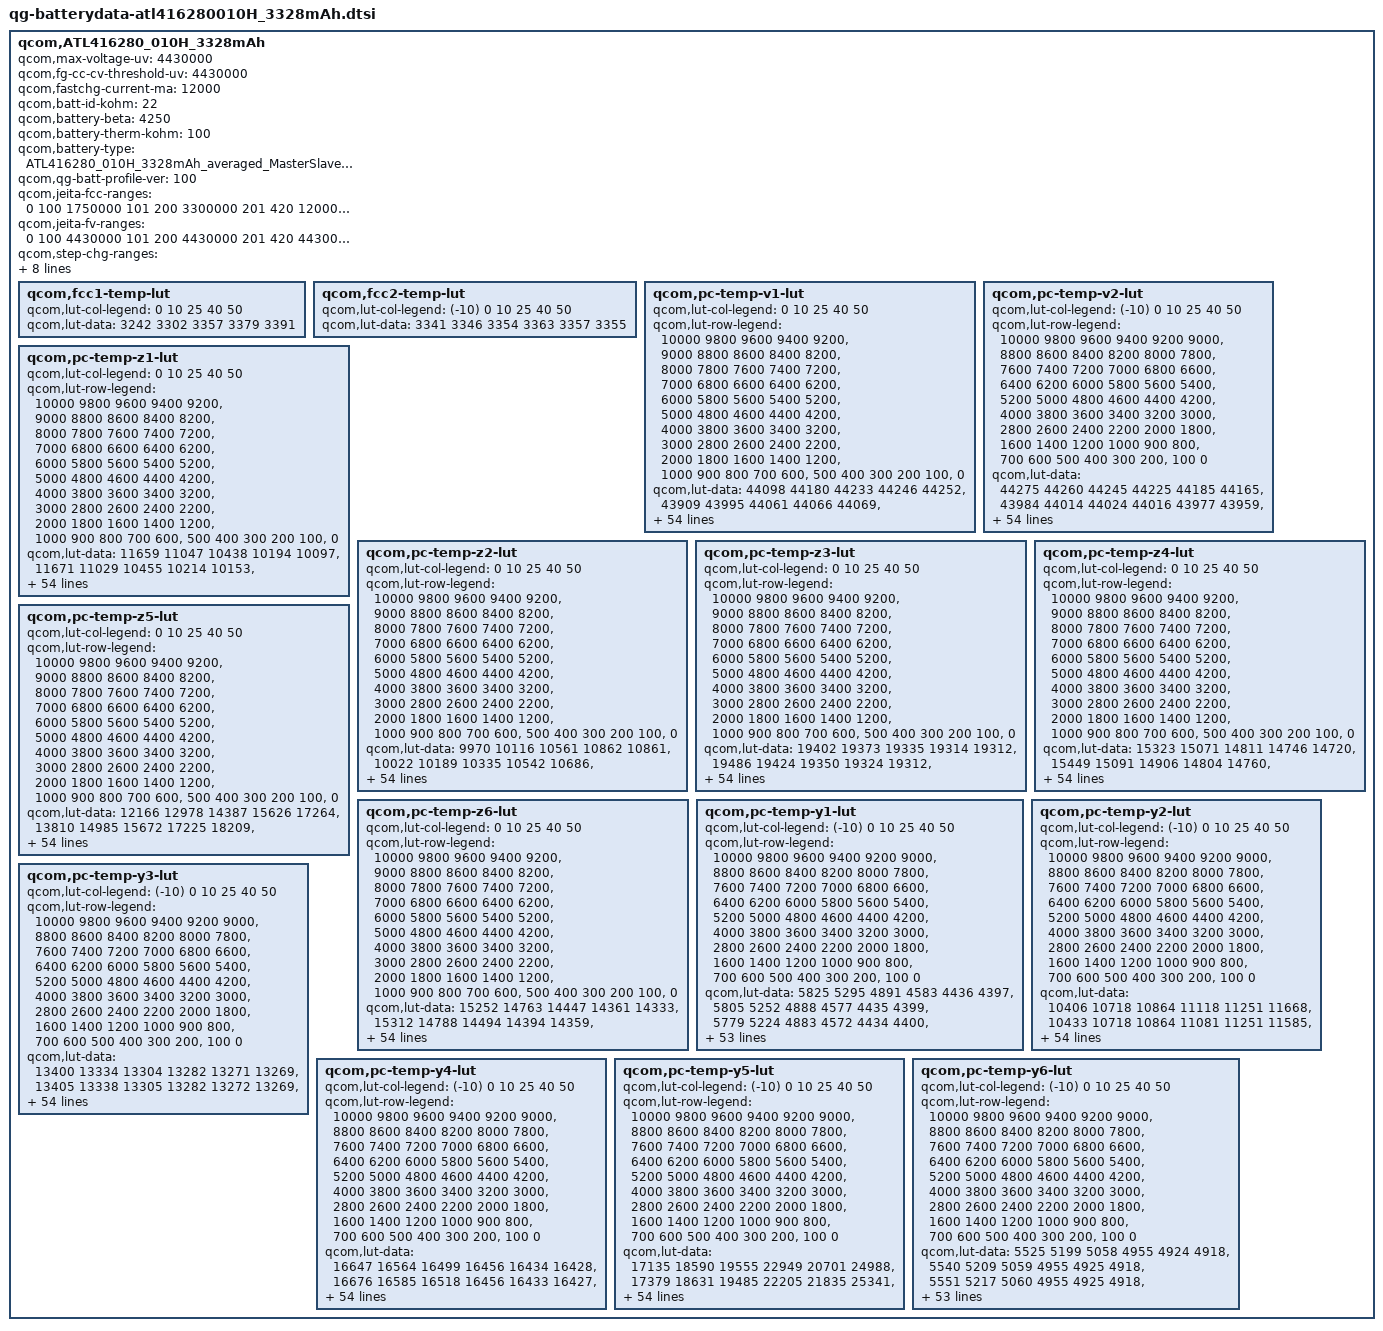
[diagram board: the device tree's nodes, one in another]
qcom,ATL416280_010H_3328mAh {
	/* ATL416280_010H_3328mAh_averaged_MasterSlave_Aug1th2020 */
	qcom,max-voltage-uv = <4430000>;
	qcom,fg-cc-cv-threshold-uv = <4430000>;
	qcom,fastchg-current-ma = <12000>;
	qcom,batt-id-kohm = <22>;
	qcom,battery-beta = <4250>;
	qcom,battery-therm-kohm = <100>;
	qcom,battery-type = "ATL416280_010H_3328mAh_averaged_MasterSlave_Aug1th2020";
	qcom,qg-batt-profile-ver = <100>;

	qcom,jeita-fcc-ranges = <0  100  1750000
				101 200  3300000
				201 420  12000000
				421 434  8000000
				435 450  7000000
				451 550  1750000>;
	qcom,jeita-fv-ranges = <0   100  4430000
				101 200  4430000
				201 420  4430000
				421 434  4430000
				435 450  4430000
				451 550  4100000>;
	qcom,step-chg-ranges = <3500000  4000000  12000000
				4000001  4200000  8000000
				4200001  4400000  6000000>;

	qcom,ocv-based-step-chg;
	/* Rise-Hys = 1 DeciDegC, Fall-Hys=10 deciDegC */
	qcom,step-jeita-hysteresis = <1 10>;
	/* COOL = 10 degc, WARM = 45 degC */
	qcom,jeita-soft-thresholds = <0x4ccc 0x20b8>;
	/* COLD = 0 degC, HOT = 55 degC*/
	qcom,jeita-hard-thresholds = <0x58cd 0x181d>;
	/* COOL hys = 13 degC, WARM hys = 42 degC */
	qcom,jeita-soft-hys-thresholds = <0x48d4 0x23c0>;
	qcom,jeita-soft-fcc-ua = <1750000 1750000>;
	qcom,jeita-soft-fv-uv = <4430000 4100000>;

	qcom,fcc1-temp-lut {
		qcom,lut-col-legend = <0 10 25 40 50>;
		qcom,lut-data = <3242 3302 3357 3379 3391>;
	};

	qcom,fcc2-temp-lut {
		qcom,lut-col-legend = <(-10) 0 10 25 40 50>;
		qcom,lut-data = <3341 3346 3354 3363 3357 3355>;
	};

	qcom,pc-temp-v1-lut {
		qcom,lut-col-legend = <0 10 25 40 50>;
		qcom,lut-row-legend = <10000 9800 9600 9400 9200>,
			<9000 8800 8600 8400 8200>,
			<8000 7800 7600 7400 7200>,
			<7000 6800 6600 6400 6200>,
			<6000 5800 5600 5400 5200>,
			<5000 4800 4600 4400 4200>,
			<4000 3800 3600 3400 3200>,
			<3000 2800 2600 2400 2200>,
			<2000 1800 1600 1400 1200>,
			<1000 900 800 700 600>,
			<500 400 300 200 100>,
			<0>;
		qcom,lut-data = <44098 44180 44233 44246 44252>,
			<43909 43995 44061 44066 44069>,
			<43705 43801 43872 43881 43883>,
			<43488 43600 43675 43687 43692>,
			<43266 43388 43468 43485 43492>,
			<43036 43167 43250 43272 43280>,
			<42803 42933 43024 43049 43059>,
			<42570 42694 42788 42815 42828>,
			<42337 42459 42550 42577 42592>,
			<42108 42224 42310 42340 42357>,
			<41884 41993 42071 42103 42121>,
			<41664 41767 41836 41868 41887>,
			<41448 41545 41606 41636 41655>,
			<41237 41324 41380 41407 41425>,
			<41030 41106 41160 41185 41202>,
			<40832 40899 40947 40969 40984>,
			<40639 40702 40742 40761 40775>,
			<40451 40513 40544 40561 40575>,
			<40276 40334 40354 40367 40382>,
			<40089 40161 40180 40188 40200>,
			<39853 39958 39999 40011 40022>,
			<39582 39678 39766 39793 39811>,
			<39373 39405 39491 39524 39545>,
			<39227 39230 39274 39293 39307>,
			<39106 39100 39118 39127 39139>,
			<38995 38979 38986 38988 38998>,
			<38895 38860 38860 38860 38868>,
			<38802 38751 38746 38743 38748>,
			<38713 38654 38641 38636 38638>,
			<38631 38565 38544 38537 38534>,
			<38558 38484 38455 38445 38438>,
			<38490 38409 38373 38358 38349>,
			<38430 38341 38297 38277 38267>,
			<38374 38282 38231 38203 38190>,
			<38323 38230 38175 38142 38123>,
			<38276 38182 38122 38082 38055>,
			<38238 38140 38068 38014 37975>,
			<38193 38097 38013 37939 37885>,
			<38116 38027 37940 37854 37788>,
			<38003 37919 37837 37754 37682>,
			<37879 37797 37720 37642 37567>,
			<37742 37666 37593 37514 37436>,
			<37590 37521 37452 37370 37291>,
			<37414 37347 37288 37207 37133>,
			<37268 37201 37151 37083 37015>,
			<37186 37123 37070 37016 36960>,
			<37165 37094 37046 37000 36942>,
			<37137 37072 37031 36984 36926>,
			<37105 37045 37004 36958 36896>,
			<37020 36948 36883 36809 36725>,
			<36678 36608 36539 36461 36372>,
			<36216 36138 36070 35995 35905>,
			<35609 35533 35468 35397 35306>,
			<34786 34707 34651 34586 34492>,
			<33476 33410 33391 33343 33244>,
			<30000 30000 30000 30000 30000>;
	};

	qcom,pc-temp-v2-lut {
		qcom,lut-col-legend = <(-10) 0 10 25 40 50>;
		qcom,lut-row-legend = <10000 9800 9600 9400 9200 9000>,
			<8800 8600 8400 8200 8000 7800>,
			<7600 7400 7200 7000 6800 6600>,
			<6400 6200 6000 5800 5600 5400>,
			<5200 5000 4800 4600 4400 4200>,
			<4000 3800 3600 3400 3200 3000>,
			<2800 2600 2400 2200 2000 1800>,
			<1600 1400 1200 1000 900 800>,
			<700 600 500 400 300 200>,
			<100 0>;
		qcom,lut-data = <44275 44260 44245 44225 44185 44165>,
			<43984 44014 44024 44016 43977 43959>,
			<43712 43777 43806 43807 43768 43752>,
			<43460 43552 43593 43599 43560 43545>,
			<43231 43339 43387 43392 43353 43338>,
			<43003 43122 43174 43178 43139 43124>,
			<42768 42890 42942 42949 42911 42898>,
			<42529 42651 42702 42713 42676 42664>,
			<42287 42411 42464 42476 42441 42430>,
			<42038 42168 42223 42235 42203 42193>,
			<41795 41929 41986 41997 41967 41958>,
			<41553 41694 41750 41761 41733 41724>,
			<41322 41466 41518 41529 41503 41495>,
			<41123 41245 41291 41300 41276 41269>,
			<40954 41029 41068 41076 41055 41049>,
			<40762 40821 40853 40859 40841 40835>,
			<40509 40629 40648 40651 40635 40630>,
			<40228 40433 40445 40447 40435 40430>,
			<39961 40192 40228 40253 40245 40241>,
			<39697 39904 40000 40066 40064 40061>,
			<39454 39638 39767 39855 39860 39858>,
			<39239 39411 39515 39587 39596 39595>,
			<39041 39206 39275 39324 39333 39333>,
			<38861 39024 39085 39127 39137 39140>,
			<38695 38861 38925 38961 38976 38983>,
			<38542 38712 38780 38815 38833 38843>,
			<38393 38578 38648 38686 38706 38717>,
			<38263 38454 38529 38570 38592 38603>,
			<38174 38335 38418 38462 38485 38494>,
			<38109 38221 38314 38361 38386 38393>,
			<38052 38123 38219 38268 38294 38300>,
			<38001 38035 38132 38182 38211 38217>,
			<37953 37961 38050 38102 38132 38138>,
			<37902 37908 37970 38026 38055 38057>,
			<37850 37867 37893 37952 37980 37975>,
			<37793 37825 37826 37872 37889 37876>,
			<37728 37783 37772 37784 37772 37742>,
			<37655 37737 37716 37692 37651 37607>,
			<37572 37673 37645 37596 37550 37502>,
			<37477 37592 37562 37495 37454 37409>,
			<37369 37492 37463 37390 37350 37306>,
			<37239 37362 37338 37280 37238 37193>,
			<37109 37208 37195 37153 37108 37062>,
			<36989 37019 37034 37010 36963 36912>,
			<36895 36892 36919 36904 36873 36829>,
			<36811 36821 36864 36877 36848 36802>,
			<36770 36790 36842 36858 36832 36787>,
			<36718 36750 36809 36829 36813 36768>,
			<36641 36688 36750 36777 36763 36707>,
			<36482 36528 36596 36595 36554 36469>,
			<36148 36188 36240 36193 36155 36060>,
			<35657 35691 35728 35665 35634 35532>,
			<35006 35042 35063 34994 34970 34860>,
			<34121 34151 34173 34099 34095 33987>,
			<32801 32865 32898 32797 32800 32602>,
			<29522 29510 29509 29510 29511 29509>;
	};

	qcom,pc-temp-z1-lut {
		qcom,lut-col-legend = <0 10 25 40 50>;
		qcom,lut-row-legend = <10000 9800 9600 9400 9200>,
			<9000 8800 8600 8400 8200>,
			<8000 7800 7600 7400 7200>,
			<7000 6800 6600 6400 6200>,
			<6000 5800 5600 5400 5200>,
			<5000 4800 4600 4400 4200>,
			<4000 3800 3600 3400 3200>,
			<3000 2800 2600 2400 2200>,
			<2000 1800 1600 1400 1200>,
			<1000 900 800 700 600>,
			<500 400 300 200 100>,
			<0>;
		qcom,lut-data = <11659 11047 10438 10194 10097>,
			<11671 11029 10455 10214 10153>,
			<11655 11012 10446 10216 10156>,
			<11617 10994 10437 10216 10157>,
			<11593 10970 10431 10216 10157>,
			<11584 10953 10426 10213 10156>,
			<11576 10938 10421 10210 10154>,
			<11557 10928 10416 10208 10153>,
			<11515 10925 10412 10206 10153>,
			<11490 10923 10409 10204 10153>,
			<11497 10921 10406 10201 10153>,
			<11509 10918 10404 10200 10153>,
			<11510 10914 10402 10201 10152>,
			<11503 10910 10401 10201 10151>,
			<11498 10907 10402 10201 10151>,
			<11499 10905 10402 10200 10152>,
			<11501 10903 10403 10200 10153>,
			<11502 10902 10402 10202 10153>,
			<11502 10901 10403 10203 10154>,
			<11502 10899 10404 10204 10155>,
			<11503 10901 10406 10205 10156>,
			<11509 10906 10409 10207 10158>,
			<11512 10913 10414 10209 10159>,
			<11514 10923 10418 10211 10160>,
			<11517 10937 10421 10213 10161>,
			<11519 10943 10424 10216 10162>,
			<11527 10939 10428 10218 10164>,
			<11537 10934 10433 10220 10166>,
			<11555 10934 10437 10222 10167>,
			<11574 10941 10440 10225 10169>,
			<11575 10944 10444 10227 10169>,
			<11562 10940 10448 10229 10171>,
			<11550 10937 10453 10232 10173>,
			<11543 10941 10458 10235 10176>,
			<11537 10956 10463 10238 10178>,
			<11538 10970 10468 10241 10180>,
			<11555 10977 10474 10244 10182>,
			<11572 10984 10480 10247 10185>,
			<11581 10994 10485 10250 10187>,
			<11596 11009 10489 10252 10190>,
			<11607 11021 10493 10254 10193>,
			<11619 11029 10500 10256 10193>,
			<11626 11035 10508 10258 10193>,
			<11620 11040 10511 10260 10195>,
			<11612 11043 10514 10261 10196>,
			<11669 11023 10519 10262 10197>,
			<11664 11068 10522 10262 10196>,
			<11640 11047 10525 10264 10197>,
			<11614 11029 10532 10266 10198>,
			<11674 11061 10534 10269 10200>,
			<11686 11062 10540 10272 10201>,
			<11641 11086 10551 10274 10204>,
			<11689 11079 10562 10280 10208>,
			<11716 11113 10568 10287 10213>,
			<11716 11113 10568 10287 10213>,
			<11716 11113 10568 10287 10213>;
	};

	qcom,pc-temp-z2-lut {
		qcom,lut-col-legend = <0 10 25 40 50>;
		qcom,lut-row-legend = <10000 9800 9600 9400 9200>,
			<9000 8800 8600 8400 8200>,
			<8000 7800 7600 7400 7200>,
			<7000 6800 6600 6400 6200>,
			<6000 5800 5600 5400 5200>,
			<5000 4800 4600 4400 4200>,
			<4000 3800 3600 3400 3200>,
			<3000 2800 2600 2400 2200>,
			<2000 1800 1600 1400 1200>,
			<1000 900 800 700 600>,
			<500 400 300 200 100>,
			<0>;
		qcom,lut-data = <9970 10116 10561 10862 10861>,
			<10022 10189 10335 10542 10686>,
			<10053 10227 10328 10500 10635>,
			<10077 10217 10332 10460 10559>,
			<10085 10192 10330 10444 10549>,
			<10071 10181 10327 10435 10556>,
			<10051 10179 10319 10430 10560>,
			<10039 10177 10300 10427 10572>,
			<10030 10311 10282 10425 10589>,
			<10026 10661 10267 10429 10593>,
			<10031 10793 10255 10440 10595>,
			<10039 10769 10253 10451 10595>,
			<10043 10725 10257 10461 10589>,
			<10047 10580 10259 10469 10585>,
			<10051 10279 10266 10467 10590>,
			<10062 10177 10274 10463 10604>,
			<10079 10546 10274 10464 10616>,
			<10085 10944 10272 10474 10633>,
			<10084 10953 10271 10482 10646>,
			<10083 10857 10266 10482 10653>,
			<10087 10728 10261 10476 10658>,
			<10096 10447 10264 10459 10647>,
			<10098 10188 10274 10429 10568>,
			<10082 10163 10275 10401 10495>,
			<10064 10165 10260 10370 10465>,
			<10066 10166 10246 10345 10445>,
			<10081 10166 10243 10345 10445>,
			<10092 10168 10242 10358 10464>,
			<10096 10170 10244 10374 10487>,
			<10098 10175 10253 10392 10509>,
			<10100 10183 10266 10414 10535>,
			<10103 10197 10277 10439 10564>,
			<10107 10213 10288 10467 10598>,
			<10112 10222 10302 10494 10637>,
			<10119 10228 10320 10519 10692>,
			<10121 10232 10336 10544 10742>,
			<10122 10234 10343 10579 10769>,
			<10122 10235 10349 10620 10787>,
			<10121 10239 10363 10639 10800>,
			<10119 10247 10406 10648 10815>,
			<10115 10251 10437 10651 10824>,
			<10101 10226 10413 10644 10809>,
			<10084 10202 10382 10629 10771>,
			<10066 10204 10395 10622 10738>,
			<10076 10198 10422 10620 10715>,
			<10098 10170 10411 10625 10716>,
			<10616 10142 10403 10660 10751>,
			<12987 10159 10412 10673 10830>,
			<10369 10144 10411 10698 10854>,
			<10911 10186 10463 10600 10672>,
			<13004 10177 10420 10535 10585>,
			<12825 10142 10386 10451 10519>,
			<10169 10113 10357 10419 10449>,
			<9894 10063 10324 10350 10367>,
			<9894 10063 10324 10350 10367>,
			<9894 10063 10324 10350 10367>;
	};

	qcom,pc-temp-z3-lut {
		qcom,lut-col-legend = <0 10 25 40 50>;
		qcom,lut-row-legend = <10000 9800 9600 9400 9200>,
			<9000 8800 8600 8400 8200>,
			<8000 7800 7600 7400 7200>,
			<7000 6800 6600 6400 6200>,
			<6000 5800 5600 5400 5200>,
			<5000 4800 4600 4400 4200>,
			<4000 3800 3600 3400 3200>,
			<3000 2800 2600 2400 2200>,
			<2000 1800 1600 1400 1200>,
			<1000 900 800 700 600>,
			<500 400 300 200 100>,
			<0>;
		qcom,lut-data = <19402 19373 19335 19314 19312>,
			<19486 19424 19350 19324 19312>,
			<19532 19456 19372 19335 19320>,
			<19564 19467 19382 19345 19328>,
			<19581 19474 19382 19344 19329>,
			<19592 19475 19381 19340 19328>,
			<19599 19472 19379 19339 19327>,
			<19598 19470 19373 19339 19326>,
			<19592 19472 19369 19339 19325>,
			<19585 19479 19369 19337 19323>,
			<19578 19481 19369 19333 19319>,
			<19570 19476 19368 19330 19317>,
			<19565 19470 19367 19330 19316>,
			<19561 19463 19366 19329 19316>,
			<19558 19455 19366 19328 19315>,
			<19561 19452 19366 19327 19314>,
			<19565 19454 19366 19326 19313>,
			<19566 19458 19364 19325 19309>,
			<19556 19459 19363 19324 19305>,
			<19547 19460 19362 19322 19304>,
			<19555 19460 19361 19320 19303>,
			<19576 19457 19362 19322 19306>,
			<19584 19454 19367 19335 19324>,
			<19569 19457 19372 19345 19338>,
			<19552 19465 19379 19348 19336>,
			<19553 19469 19384 19349 19332>,
			<19562 19469 19384 19349 19329>,
			<19567 19468 19381 19346 19326>,
			<19566 19466 19377 19342 19324>,
			<19564 19461 19373 19336 19322>,
			<19561 19456 19370 19331 19320>,
			<19557 19454 19369 19329 19318>,
			<19554 19451 19368 19329 19315>,
			<19551 19450 19367 19327 19312>,
			<19548 19448 19365 19324 19308>,
			<19545 19446 19364 19322 19304>,
			<19542 19445 19363 19321 19304>,
			<19537 19443 19362 19321 19306>,
			<19532 19439 19360 19321 19309>,
			<19525 19433 19358 19321 19313>,
			<19520 19428 19355 19322 19316>,
			<19517 19425 19353 19323 19316>,
			<19514 19422 19352 19324 19316>,
			<19507 19418 19349 19326 19317>,
			<19488 19410 19344 19324 19317>,
			<19457 19397 19339 19316 19306>,
			<19366 19395 19338 19310 19302>,
			<19362 19395 19334 19307 19297>,
			<19357 19392 19333 19304 19296>,
			<19268 19388 19334 19316 19307>,
			<19352 19388 19339 19319 19308>,
			<19260 19389 19342 19322 19310>,
			<19263 19391 19343 19323 19311>,
			<19269 19393 19347 19325 19314>,
			<19269 19393 19347 19325 19314>,
			<19269 19393 19347 19325 19314>;
	};

	qcom,pc-temp-z4-lut {
		qcom,lut-col-legend = <0 10 25 40 50>;
		qcom,lut-row-legend = <10000 9800 9600 9400 9200>,
			<9000 8800 8600 8400 8200>,
			<8000 7800 7600 7400 7200>,
			<7000 6800 6600 6400 6200>,
			<6000 5800 5600 5400 5200>,
			<5000 4800 4600 4400 4200>,
			<4000 3800 3600 3400 3200>,
			<3000 2800 2600 2400 2200>,
			<2000 1800 1600 1400 1200>,
			<1000 900 800 700 600>,
			<500 400 300 200 100>,
			<0>;
		qcom,lut-data = <15323 15071 14811 14746 14720>,
			<15449 15091 14906 14804 14760>,
			<15425 15094 14869 14778 14744>,
			<15314 15056 14826 14743 14714>,
			<15205 14959 14783 14723 14698>,
			<15112 14888 14746 14706 14688>,
			<15026 14838 14732 14695 14681>,
			<14957 14801 14725 14688 14677>,
			<14896 14776 14719 14683 14673>,
			<14860 14753 14711 14677 14669>,
			<14846 14743 14703 14673 14665>,
			<14838 14739 14696 14668 14661>,
			<14832 14736 14691 14662 14657>,
			<14827 14737 14687 14657 14652>,
			<14824 14747 14681 14652 14647>,
			<14821 14751 14677 14648 14643>,
			<14818 14748 14675 14644 14639>,
			<14817 14742 14674 14640 14635>,
			<14824 14733 14673 14638 14633>,
			<14835 14720 14674 14638 14633>,
			<14869 14719 14676 14640 14632>,
			<14935 14811 14704 14651 14637>,
			<14964 14912 14774 14695 14666>,
			<14968 14907 14800 14719 14688>,
			<14969 14862 14775 14710 14684>,
			<14960 14830 14744 14695 14678>,
			<14926 14812 14731 14686 14672>,
			<14902 14801 14722 14680 14668>,
			<14894 14799 14717 14676 14664>,
			<14889 14797 14713 14672 14660>,
			<14889 14797 14711 14669 14655>,
			<14888 14800 14712 14667 14652>,
			<14888 14805 14714 14664 14648>,
			<14889 14809 14716 14664 14647>,
			<14889 14812 14718 14664 14647>,
			<14888 14814 14720 14665 14647>,
			<14880 14810 14722 14671 14651>,
			<14869 14803 14724 14682 14661>,
			<14858 14795 14725 14686 14664>,
			<14846 14785 14723 14684 14663>,
			<14831 14773 14720 14681 14662>,
			<14808 14756 14712 14677 14662>,
			<14783 14736 14700 14673 14663>,
			<14757 14718 14691 14671 14663>,
			<14708 14684 14673 14661 14655>,
			<14697 14658 14649 14642 14634>,
			<14784 14650 14640 14636 14627>,
			<14781 14642 14631 14627 14620>,
			<14781 14638 14627 14623 14617>,
			<14867 14643 14634 14629 14627>,
			<14786 14648 14635 14631 14630>,
			<14884 14648 14632 14631 14630>,
			<14887 14647 14633 14629 14630>,
			<14890 14653 14631 14628 14627>,
			<14890 14653 14631 14628 14627>,
			<14890 14653 14631 14628 14627>;
	};

	qcom,pc-temp-z5-lut {
		qcom,lut-col-legend = <0 10 25 40 50>;
		qcom,lut-row-legend = <10000 9800 9600 9400 9200>,
			<9000 8800 8600 8400 8200>,
			<8000 7800 7600 7400 7200>,
			<7000 6800 6600 6400 6200>,
			<6000 5800 5600 5400 5200>,
			<5000 4800 4600 4400 4200>,
			<4000 3800 3600 3400 3200>,
			<3000 2800 2600 2400 2200>,
			<2000 1800 1600 1400 1200>,
			<1000 900 800 700 600>,
			<500 400 300 200 100>,
			<0>;
		qcom,lut-data = <12166 12978 14387 15626 17264>,
			<13810 14985 15672 17225 18209>,
			<15037 16493 17005 18525 19656>,
			<16037 17364 18130 20090 21302>,
			<17042 17990 19296 20715 22477>,
			<18062 18830 20171 21184 23592>,
			<19131 20053 20176 21693 24369>,
			<20493 21291 19681 22495 24870>,
			<22231 22594 19402 23048 25178>,
			<23342 24078 19833 22854 24986>,
			<23672 24589 20543 22416 24269>,
			<23893 24316 21009 22353 23973>,
			<24197 23924 21366 22940 24488>,
			<24550 23702 21812 23749 25377>,
			<25080 23600 22610 24520 26648>,
			<26927 23759 23464 25394 28294>,
			<29695 24635 23994 26387 28695>,
			<30190 25552 24406 27700 27369>,
			<26930 25816 24707 28401 26067>,
			<23905 25931 24985 28024 25881>,
			<26969 25935 25166 27052 25755>,
			<35357 25058 23743 25201 25338>,
			<38580 24032 19664 21137 23741>,
			<32373 23635 18078 18965 22294>,
			<25338 22897 18940 19760 21598>,
			<24828 22638 20253 21187 21129>,
			<26033 24566 21420 22397 21195>,
			<27396 27228 22656 23635 21949>,
			<28852 28533 23790 24118 22872>,
			<30272 29380 24758 23956 23997>,
			<31085 30139 25798 23761 25347>,
			<31648 31024 27315 24682 26681>,
			<31965 31705 29100 27689 28118>,
			<32090 31848 30185 29253 28672>,
			<32169 31842 30889 29601 28233>,
			<32161 31783 31245 29771 27444>,
			<31966 31595 30930 28844 26330>,
			<31797 31309 30138 26450 24726>,
			<31866 31038 29492 25645 24398>,
			<32041 30746 28906 25994 28212>,
			<32110 30410 28447 26540 32157>,
			<32035 29896 28199 27794 32900>,
			<32065 29535 27909 29411 33191>,
			<32268 29645 26421 29797 33021>,
			<33608 31803 26102 28554 32432>,
			<28165 28251 28148 26847 25119>,
			<20020 29070 31258 25585 26060>,
			<19720 29362 29926 29347 29885>,
			<19151 29115 30760 29197 33424>,
			<11441 26259 25926 31327 32841>,
			<17371 24364 25904 30568 29500>,
			<10909 24143 27288 30083 28672>,
			<10880 24216 26543 29832 27070>,
			<10863 23238 27543 28980 27969>,
			<10863 23238 27543 28980 27969>,
			<10863 23238 27543 28980 27969>;
	};

	qcom,pc-temp-z6-lut {
		qcom,lut-col-legend = <0 10 25 40 50>;
		qcom,lut-row-legend = <10000 9800 9600 9400 9200>,
			<9000 8800 8600 8400 8200>,
			<8000 7800 7600 7400 7200>,
			<7000 6800 6600 6400 6200>,
			<6000 5800 5600 5400 5200>,
			<5000 4800 4600 4400 4200>,
			<4000 3800 3600 3400 3200>,
			<3000 2800 2600 2400 2200>,
			<2000 1800 1600 1400 1200>,
			<1000 900 800 700 600>,
			<500 400 300 200 100>,
			<0>;
		qcom,lut-data = <15252 14763 14447 14361 14333>,
			<15312 14788 14494 14394 14359>,
			<15297 14794 14487 14389 14355>,
			<15233 14775 14477 14380 14348>,
			<15169 14725 14460 14371 14342>,
			<15111 14686 14440 14361 14337>,
			<15055 14655 14429 14355 14333>,
			<15004 14633 14423 14352 14330>,
			<14954 14621 14418 14348 14328>,
			<14922 14614 14413 14344 14325>,
			<14907 14607 14409 14340 14322>,
			<14897 14600 14405 14337 14319>,
			<14889 14595 14402 14334 14316>,
			<14882 14592 14400 14331 14313>,
			<14878 14589 14397 14329 14311>,
			<14878 14588 14395 14326 14309>,
			<14878 14589 14394 14324 14306>,
			<14878 14589 14393 14322 14303>,
			<14877 14586 14392 14321 14300>,
			<14876 14580 14393 14320 14299>,
			<14892 14580 14394 14320 14299>,
			<14933 14619 14407 14326 14302>,
			<14950 14662 14442 14353 14326>,
			<14948 14662 14455 14369 14343>,
			<14944 14649 14449 14367 14341>,
			<14940 14639 14440 14362 14336>,
			<14935 14634 14434 14358 14333>,
			<14932 14630 14429 14354 14330>,
			<14932 14628 14426 14351 14327>,
			<14931 14625 14423 14346 14324>,
			<14931 14625 14421 14342 14321>,
			<14931 14626 14421 14341 14318>,
			<14931 14629 14422 14339 14316>,
			<14933 14632 14423 14339 14313>,
			<14936 14636 14424 14338 14311>,
			<14937 14638 14425 14337 14309>,
			<14936 14638 14427 14339 14311>,
			<14935 14638 14428 14344 14316>,
			<14935 14637 14429 14346 14320>,
			<14935 14634 14428 14346 14322>,
			<14934 14631 14426 14345 14323>,
			<14931 14626 14423 14345 14324>,
			<14928 14621 14418 14344 14324>,
			<14926 14617 14415 14344 14325>,
			<14914 14607 14406 14340 14322>,
			<14905 14593 14394 14327 14307>,
			<14900 14591 14390 14321 14302>,
			<14902 14589 14385 14316 14296>,
			<14906 14589 14384 14313 14294>,
			<14908 14594 14388 14322 14305>,
			<14925 14601 14393 14326 14308>,
			<14930 14607 14396 14328 14309>,
			<14948 14614 14399 14329 14311>,
			<14968 14628 14404 14331 14313>,
			<14968 14628 14404 14331 14313>,
			<14968 14628 14404 14331 14313>;
	};

	qcom,pc-temp-y1-lut {
		qcom,lut-col-legend = <(-10) 0 10 25 40 50>;
		qcom,lut-row-legend = <10000 9800 9600 9400 9200 9000>,
			<8800 8600 8400 8200 8000 7800>,
			<7600 7400 7200 7000 6800 6600>,
			<6400 6200 6000 5800 5600 5400>,
			<5200 5000 4800 4600 4400 4200>,
			<4000 3800 3600 3400 3200 3000>,
			<2800 2600 2400 2200 2000 1800>,
			<1600 1400 1200 1000 900 800>,
			<700 600 500 400 300 200>,
			<100 0>;
		qcom,lut-data = <5825 5295 4891 4583 4436 4397>,
			<5805 5252 4888 4577 4435 4399>,
			<5779 5224 4883 4572 4434 4400>,
			<5752 5208 4878 4567 4433 4400>,
			<5731 5200 4873 4563 4432 4400>,
			<5722 5199 4867 4559 4431 4400>,
			<5723 5211 4861 4556 4430 4399>,
			<5725 5228 4855 4554 4429 4398>,
			<5725 5231 4852 4551 4428 4398>,
			<5716 5228 4850 4548 4427 4397>,
			<5712 5224 4849 4546 4426 4397>,
			<5716 5213 4847 4543 4426 4396>,
			<5721 5200 4844 4541 4425 4396>,
			<5726 5195 4841 4540 4425 4395>,
			<5732 5187 4836 4539 4425 4395>,
			<5735 5182 4832 4538 4424 4395>,
			<5723 5192 4830 4538 4424 4395>,
			<5707 5206 4828 4538 4423 4395>,
			<5706 5212 4829 4538 4424 4396>,
			<5722 5215 4830 4538 4424 4396>,
			<5731 5218 4832 4538 4425 4397>,
			<5742 5217 4835 4540 4425 4397>,
			<5756 5216 4837 4543 4426 4397>,
			<5753 5219 4838 4545 4427 4397>,
			<5745 5229 4836 4546 4428 4399>,
			<5740 5233 4837 4548 4429 4399>,
			<5745 5223 4842 4551 4430 4400>,
			<5752 5211 4848 4554 4430 4400>,
			<5751 5213 4853 4557 4432 4401>,
			<5745 5226 4861 4560 4433 4402>,
			<5744 5235 4864 4562 4435 4403>,
			<5756 5239 4869 4565 4437 4404>,
			<5771 5242 4874 4567 4439 4405>,
			<5770 5242 4878 4571 4440 4406>,
			<5758 5239 4883 4575 4441 4407>,
			<5751 5240 4886 4579 4443 4408>,
			<5749 5250 4888 4584 4444 4408>,
			<5750 5260 4888 4587 4446 4409>,
			<5752 5258 4890 4588 4447 4410>,
			<5754 5249 4895 4589 4448 4411>,
			<5756 5246 4897 4590 4449 4412>,
			<5737 5246 4899 4594 4449 4413>,
			<5728 5248 4906 4599 4450 4413>,
			<5760 5258 4934 4605 4453 4415>,
			<5783 5257 4934 4606 4454 4416>,
			<5771 5268 4921 4612 4456 4417>,
			<5761 5294 4944 4614 4455 4416>,
			<5781 5291 4939 4616 4456 4416>,
			<5781 5282 4945 4620 4455 4417>,
			<5793 5272 4939 4617 4457 4417>,
			<5829 5269 4962 4621 4458 4418>,
			<5898 5289 4954 4625 4459 4420>,
			<5957 5303 4959 4635 4462 4423>,
			<6001 5356 4978 4642 4464 4423>,
			<6001 5356 4978 4642 4464 4423>,
			<6001 5356 4978 4642 4464 4423>;
	};

	qcom,pc-temp-y2-lut {
		qcom,lut-col-legend = <(-10) 0 10 25 40 50>;
		qcom,lut-row-legend = <10000 9800 9600 9400 9200 9000>,
			<8800 8600 8400 8200 8000 7800>,
			<7600 7400 7200 7000 6800 6600>,
			<6400 6200 6000 5800 5600 5400>,
			<5200 5000 4800 4600 4400 4200>,
			<4000 3800 3600 3400 3200 3000>,
			<2800 2600 2400 2200 2000 1800>,
			<1600 1400 1200 1000 900 800>,
			<700 600 500 400 300 200>,
			<100 0>;
		qcom,lut-data = <10406 10718 10864 11118 11251 11668>,
			<10433 10718 10864 11081 11251 11585>,
			<10467 10715 10856 11043 11236 11483>,
			<10501 10709 10842 11006 11211 11381>,
			<10527 10703 10827 10970 11182 11296>,
			<10541 10695 10813 10937 11154 11247>,
			<10544 10683 10791 10900 11115 11229>,
			<10544 10671 10768 10869 11076 11216>,
			<10544 10666 10758 10858 11063 11194>,
			<10545 10663 10747 10854 11055 11162>,
			<10548 10661 10742 10856 11047 11144>,
			<10584 10675 10743 10872 11030 11136>,
			<10643 10699 10743 10891 11011 11128>,
			<10679 10720 10751 10896 11007 11123>,
			<10706 10740 10780 10898 11007 11119>,
			<10722 10766 10815 10900 11005 11116>,
			<10731 10828 10858 10906 10992 11113>,
			<10737 10888 10906 10919 10979 11112>,
			<10733 10887 10950 10975 11007 11127>,
			<10719 10851 10995 11106 11112 11177>,
			<10702 10831 11011 11157 11174 11232>,
			<10677 10832 10968 11087 11187 11293>,
			<10649 10834 10919 11015 11198 11353>,
			<10623 10830 10918 11018 11222 11402>,
			<10596 10819 10927 11039 11260 11445>,
			<10570 10807 10933 11052 11285 11464>,
			<10551 10796 10938 11067 11299 11470>,
			<10528 10785 10943 11079 11314 11474>,
			<10429 10769 10944 11088 11332 11489>,
			<10166 10749 10946 11103 11355 11521>,
			<9971 10742 10948 11114 11368 11545>,
			<9866 10758 10955 11138 11376 11578>,
			<9788 10777 10958 11160 11387 11615>,
			<9748 10775 10938 11170 11407 11646>,
			<9721 10761 10898 11179 11434 11674>,
			<9705 10746 10886 11176 11447 11678>,
			<9694 10730 10896 11148 11434 11627>,
			<9686 10709 10904 11126 11420 11577>,
			<9681 10680 10899 11126 11411 11571>,
			<9676 10636 10880 11132 11394 11573>,
			<9673 10571 10846 11135 11383 11565>,
			<9670 10421 10760 11134 11366 11537>,
			<9667 10231 10672 11124 11363 11515>,
			<9666 9896 10595 11095 11376 11475>,
			<9664 9751 10465 11027 11349 11442>,
			<9662 9727 10440 11031 11317 11338>,
			<9661 9706 10454 11006 11217 11292>,
			<9659 9689 10373 10993 11176 11242>,
			<9658 9680 10333 10964 11170 11260>,
			<9656 9673 10331 11011 11154 11255>,
			<9652 9667 10184 10960 11153 11166>,
			<9650 9662 10071 10918 11116 11067>,
			<9648 9656 9935 10869 10995 11030>,
			<9648 9651 9745 10902 10894 10882>,
			<9648 9651 9745 10902 10894 10882>,
			<9648 9651 9745 10902 10894 10882>;
	};

	qcom,pc-temp-y3-lut {
		qcom,lut-col-legend = <(-10) 0 10 25 40 50>;
		qcom,lut-row-legend = <10000 9800 9600 9400 9200 9000>,
			<8800 8600 8400 8200 8000 7800>,
			<7600 7400 7200 7000 6800 6600>,
			<6400 6200 6000 5800 5600 5400>,
			<5200 5000 4800 4600 4400 4200>,
			<4000 3800 3600 3400 3200 3000>,
			<2800 2600 2400 2200 2000 1800>,
			<1600 1400 1200 1000 900 800>,
			<700 600 500 400 300 200>,
			<100 0>;
		qcom,lut-data = <13400 13334 13304 13282 13271 13269>,
			<13405 13338 13305 13282 13272 13269>,
			<13410 13341 13308 13283 13273 13270>,
			<13415 13345 13310 13284 13273 13270>,
			<13419 13348 13312 13284 13274 13270>,
			<13422 13350 13313 13285 13274 13271>,
			<13425 13352 13314 13285 13275 13271>,
			<13427 13354 13314 13286 13275 13272>,
			<13426 13355 13315 13286 13276 13272>,
			<13422 13357 13316 13287 13276 13273>,
			<13419 13357 13317 13287 13277 13273>,
			<13422 13357 13318 13288 13277 13274>,
			<13426 13356 13318 13288 13278 13274>,
			<13422 13355 13318 13289 13278 13275>,
			<13403 13353 13318 13289 13278 13275>,
			<13392 13350 13317 13289 13279 13275>,
			<13393 13347 13316 13290 13280 13277>,
			<13395 13344 13314 13291 13282 13278>,
			<13393 13341 13314 13291 13283 13279>,
			<13383 13338 13313 13291 13283 13279>,
			<13374 13335 13313 13291 13284 13279>,
			<13369 13331 13309 13288 13280 13276>,
			<13366 13328 13304 13285 13276 13271>,
			<13363 13326 13302 13283 13274 13270>,
			<13362 13325 13301 13282 13273 13270>,
			<13359 13324 13301 13281 13272 13270>,
			<13349 13322 13300 13281 13272 13270>,
			<13338 13321 13300 13280 13272 13270>,
			<13337 13320 13299 13280 13272 13270>,
			<13338 13319 13299 13281 13272 13270>,
			<13340 13317 13299 13281 13272 13270>,
			<13349 13316 13298 13281 13272 13270>,
			<13363 13315 13298 13281 13272 13271>,
			<13375 13315 13297 13281 13272 13271>,
			<13387 13316 13297 13281 13273 13271>,
			<13400 13318 13296 13280 13273 13270>,
			<13414 13320 13297 13280 13272 13269>,
			<13430 13322 13298 13279 13271 13269>,
			<13452 13324 13298 13278 13271 13269>,
			<13483 13327 13299 13277 13271 13269>,
			<13519 13329 13299 13277 13271 13269>,
			<13562 13332 13300 13277 13271 13270>,
			<13612 13335 13301 13278 13271 13270>,
			<13670 13344 13302 13279 13272 13269>,
			<13763 13361 13304 13279 13271 13269>,
			<13806 13373 13304 13280 13273 13271>,
			<13898 13390 13308 13282 13274 13272>,
			<13999 13414 13311 13282 13276 13273>,
			<14126 13449 13316 13285 13277 13273>,
			<14359 13491 13323 13286 13275 13272>,
			<14914 13559 13326 13285 13275 13272>,
			<16032 13696 13336 13287 13276 13273>,
			<18313 14065 13356 13290 13278 13275>,
			<23239 15049 13424 13296 13280 13277>,
			<23239 15049 13424 13296 13280 13277>,
			<23239 15049 13424 13296 13280 13277>;
	};

	qcom,pc-temp-y4-lut {
		qcom,lut-col-legend = <(-10) 0 10 25 40 50>;
		qcom,lut-row-legend = <10000 9800 9600 9400 9200 9000>,
			<8800 8600 8400 8200 8000 7800>,
			<7600 7400 7200 7000 6800 6600>,
			<6400 6200 6000 5800 5600 5400>,
			<5200 5000 4800 4600 4400 4200>,
			<4000 3800 3600 3400 3200 3000>,
			<2800 2600 2400 2200 2000 1800>,
			<1600 1400 1200 1000 900 800>,
			<700 600 500 400 300 200>,
			<100 0>;
		qcom,lut-data = <16647 16564 16499 16456 16434 16428>,
			<16676 16585 16518 16456 16433 16427>,
			<16732 16618 16534 16456 16432 16427>,
			<16796 16652 16547 16456 16431 16426>,
			<16849 16679 16554 16456 16430 16426>,
			<16873 16689 16557 16456 16430 16426>,
			<16874 16687 16552 16456 16430 16425>,
			<16876 16682 16546 16456 16430 16425>,
			<16878 16679 16544 16456 16431 16425>,
			<16883 16677 16543 16457 16432 16426>,
			<16888 16676 16543 16459 16433 16426>,
			<16892 16684 16547 16462 16435 16428>,
			<16897 16701 16556 16465 16438 16429>,
			<16928 16721 16567 16470 16441 16432>,
			<17031 16748 16585 16478 16446 16435>,
			<17088 16779 16607 16487 16451 16439>,
			<17032 16822 16648 16499 16456 16442>,
			<16933 16859 16685 16515 16463 16446>,
			<16858 16842 16684 16541 16478 16457>,
			<16791 16751 16666 16576 16504 16476>,
			<16738 16676 16640 16587 16514 16484>,
			<16702 16638 16589 16543 16490 16467>,
			<16671 16609 16538 16489 16458 16445>,
			<16637 16588 16517 16469 16446 16437>,
			<16602 16573 16506 16456 16438 16432>,
			<16576 16560 16500 16453 16435 16430>,
			<16558 16550 16498 16454 16436 16431>,
			<16547 16540 16497 16455 16437 16431>,
			<16550 16527 16497 16458 16440 16433>,
			<16565 16511 16498 16462 16444 16436>,
			<16578 16498 16498 16466 16449 16440>,
			<16587 16488 16499 16473 16456 16446>,
			<16594 16481 16500 16479 16463 16451>,
			<16604 16485 16496 16484 16470 16457>,
			<16615 16498 16486 16489 16476 16461>,
			<16625 16514 16483 16489 16477 16462>,
			<16636 16535 16486 16480 16461 16449>,
			<16644 16555 16491 16467 16445 16437>,
			<16646 16571 16492 16453 16440 16436>,
			<16648 16584 16494 16439 16438 16436>,
			<16647 16588 16496 16437 16436 16436>,
			<16631 16581 16500 16439 16435 16436>,
			<16618 16570 16506 16443 16433 16435>,
			<16615 16553 16513 16447 16431 16432>,
			<16620 16556 16514 16440 16423 16420>,
			<16616 16555 16506 16448 16428 16425>,
			<16632 16569 16517 16453 16433 16433>,
			<16661 16593 16535 16465 16449 16460>,
			<16693 16628 16564 16488 16485 16491>,
			<16732 16645 16589 16489 16450 16444>,
			<16836 16650 16590 16471 16435 16433>,
			<17102 16663 16601 16483 16441 16437>,
			<17978 16769 16636 16515 16460 16457>,
			<21515 17404 16713 16589 16530 16537>,
			<21515 17404 16713 16589 16530 16537>,
			<21515 17404 16713 16589 16530 16537>;
	};

	qcom,pc-temp-y5-lut {
		qcom,lut-col-legend = <(-10) 0 10 25 40 50>;
		qcom,lut-row-legend = <10000 9800 9600 9400 9200 9000>,
			<8800 8600 8400 8200 8000 7800>,
			<7600 7400 7200 7000 6800 6600>,
			<6400 6200 6000 5800 5600 5400>,
			<5200 5000 4800 4600 4400 4200>,
			<4000 3800 3600 3400 3200 3000>,
			<2800 2600 2400 2200 2000 1800>,
			<1600 1400 1200 1000 900 800>,
			<700 600 500 400 300 200>,
			<100 0>;
		qcom,lut-data = <17135 18590 19555 22949 20701 24988>,
			<17379 18631 19485 22205 21835 25341>,
			<17646 18664 19414 21484 22513 25554>,
			<17914 18689 19340 20815 22830 25659>,
			<18161 18700 19265 20225 22878 25692>,
			<18366 18697 19189 19740 22751 25682>,
			<18577 18681 18938 19369 22270 25457>,
			<18751 18653 18575 19041 21582 25156>,
			<18597 18547 18336 18675 21108 25024>,
			<17730 18162 18041 18261 20748 24555>,
			<17156 17675 17694 17848 20340 23976>,
			<17195 17066 17139 17479 19774 23188>,
			<17318 16400 16454 17085 19091 22171>,
			<17354 15879 15839 16503 18255 20993>,
			<17472 15400 15213 15710 17207 19504>,
			<17744 15217 14964 15174 16771 18887>,
			<20476 16359 15041 14860 16868 19219>,
			<23978 18272 15231 14675 16985 19622>,
			<24237 19623 16460 14832 16942 19314>,
			<23191 20761 20067 15540 16755 18134>,
			<22616 21682 22003 16615 16749 17613>,
			<22897 22413 22239 19321 19370 18604>,
			<23380 23025 22407 21763 22315 20110>,
			<23803 23560 22749 22112 22473 21339>,
			<24325 24051 23239 22246 22122 22598>,
			<24497 24444 23575 22243 21815 23020>,
			<20545 24782 23761 21733 21445 22875>,
			<15340 25039 23900 21189 20976 22578>,
			<14085 25166 24014 21023 20385 21589>,
			<13631 25253 24136 20949 19689 19604>,
			<13501 25212 24316 21009 19358 18821>,
			<13826 23238 24743 21262 18826 18805>,
			<14320 21002 25139 21578 18424 18870>,
			<14638 20758 25255 21851 18822 19135>,
			<14894 20775 25318 22175 19701 19691>,
			<15065 20858 25365 22826 20458 20111>,
			<15225 21404 25463 24737 21195 20411>,
			<15352 22157 25538 26089 21745 20726>,
			<15425 22780 25144 25284 22131 21332>,
			<15580 23444 24001 23508 22775 22474>,
			<15630 23625 22797 22317 23455 23751>,
			<15262 22996 21453 21477 24218 25441>,
			<14771 21833 20350 21777 25193 26763>,
			<14096 18619 19513 23428 27188 27712>,
			<14105 16305 19264 22119 26588 29771>,
			<14159 15471 19541 22742 22455 25820>,
			<14431 15368 19801 21639 23656 25878>,
			<14473 14896 18552 19555 24070 22839>,
			<14939 15080 17718 19948 19908 17759>,
			<15039 15245 18653 20987 20742 21459>,
			<12906 15448 18857 24666 25577 25346>,
			<11332 15565 18677 24283 26022 25122>,
			<10080 14282 17958 24669 27859 27674>,
			<9306 11228 17609 25183 27791 27830>,
			<9306 11228 17609 25183 27791 27830>,
			<9306 11228 17609 25183 27791 27830>;
	};

	qcom,pc-temp-y6-lut {
		qcom,lut-col-legend = <(-10) 0 10 25 40 50>;
		qcom,lut-row-legend = <10000 9800 9600 9400 9200 9000>,
			<8800 8600 8400 8200 8000 7800>,
			<7600 7400 7200 7000 6800 6600>,
			<6400 6200 6000 5800 5600 5400>,
			<5200 5000 4800 4600 4400 4200>,
			<4000 3800 3600 3400 3200 3000>,
			<2800 2600 2400 2200 2000 1800>,
			<1600 1400 1200 1000 900 800>,
			<700 600 500 400 300 200>,
			<100 0>;
		qcom,lut-data = <5525 5199 5058 4955 4924 4918>,
			<5540 5209 5059 4955 4925 4918>,
			<5551 5217 5060 4955 4925 4918>,
			<5559 5222 5060 4955 4925 4918>,
			<5563 5225 5060 4955 4925 4918>,
			<5565 5226 5060 4955 4926 4918>,
			<5562 5224 5058 4955 4926 4919>,
			<5556 5220 5053 4955 4926 4919>,
			<5551 5217 5051 4955 4927 4919>,
			<5545 5213 5050 4955 4927 4920>,
			<5542 5212 5049 4956 4928 4921>,
			<5544 5212 5050 4957 4929 4921>,
			<5548 5213 5052 4958 4930 4922>,
			<5556 5214 5054 4960 4931 4923>,
			<5570 5219 5058 4962 4933 4924>,
			<5577 5226 5063 4965 4934 4925>,
			<5565 5235 5073 4969 4937 4927>,
			<5542 5244 5082 4974 4940 4930>,
			<5521 5239 5081 4981 4945 4933>,
			<5499 5212 5076 4991 4953 4939>,
			<5484 5190 5068 4994 4956 4941>,
			<5477 5177 5051 4979 4946 4934>,
			<5471 5169 5033 4962 4934 4924>,
			<5466 5163 5027 4955 4929 4921>,
			<5461 5160 5023 4951 4926 4919>,
			<5458 5158 5022 4950 4925 4918>,
			<5456 5157 5022 4950 4925 4919>,
			<5455 5156 5023 4950 4926 4919>,
			<5458 5155 5023 4951 4926 4920>,
			<5475 5155 5025 4953 4928 4920>,
			<5494 5155 5026 4955 4929 4922>,
			<5514 5156 5028 4957 4931 4924>,
			<5536 5159 5030 4959 4934 4926>,
			<5558 5165 5029 4961 4936 4927>,
			<5582 5178 5029 4963 4938 4928>,
			<5608 5192 5029 4963 4938 4928>,
			<5638 5210 5032 4961 4933 4924>,
			<5670 5230 5036 4957 4928 4921>,
			<5707 5251 5040 4953 4927 4920>,
			<5750 5274 5045 4949 4927 4921>,
			<5794 5297 5050 4948 4926 4921>,
			<5837 5321 5058 4950 4926 4921>,
			<5887 5346 5068 4952 4926 4921>,
			<5949 5373 5080 4955 4925 4920>,
			<6039 5412 5093 4953 4923 4917>,
			<6103 5441 5093 4957 4926 4920>,
			<6193 5482 5108 4960 4929 4923>,
			<6300 5533 5124 4965 4935 4931>,
			<6438 5601 5149 4974 4945 4940>,
			<6695 5671 5176 4974 4934 4926>,
			<7274 5763 5197 4969 4929 4923>,
			<8326 5926 5240 4975 4932 4925>,
			<10371 6349 5320 4989 4939 4932>,
			<14742 7411 5471 5016 4962 4957>,
			<14742 7411 5471 5016 4962 4957>,
			<14742 7411 5471 5016 4962 4957>;
	};

};
